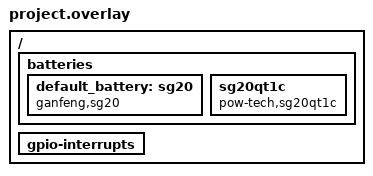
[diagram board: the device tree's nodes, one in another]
/* Copyright 2022 The ChromiumOS Authors
 * Use of this source code is governed by a BSD-style license that can be
 * found in the LICENSE file.
 */

/* zombie program common DTS includes */
#include "../adc.dtsi"
#include "../common.dtsi"
#include "../default_gpio_pinctrl.dtsi"
#include "../i2c.dtsi"
#include "../interrupts.dtsi"
#include "../keyboard.dtsi"
#include "../switchcap.dtsi"
#include "../usbc.dtsi"

/* Zombie project DTS includes*/
#include "gpio.dtsi"
#include "led_pins.dtsi"
#include "led_policy.dtsi"

/* zombie overrides follow... */
/* battery overrides */
/ {
	batteries {
		default_battery: sg20 {
			compatible = "ganfeng,sg20", "battery-smart";
		};
		sg20qt1c {
			compatible = "pow-tech,sg20qt1c", "battery-smart";
		};
	};
};

/* interrupt overrides */
/ {
	gpio-interrupts {
		/delete-node/ accel_gyro;
		/delete-node/ tablet_mode;
	};
};
